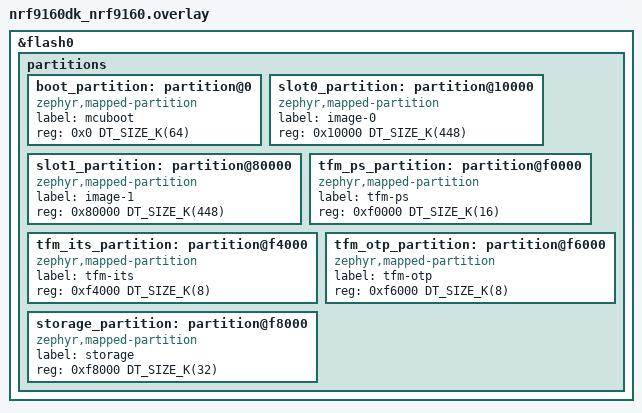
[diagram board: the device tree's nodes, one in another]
/*
 * Copyright (c) 2026 Nordic Semiconductor ASA
 *
 * SPDX-License-Identifier: LicenseRef-Nordic-5-Clause
 */

/delete-node/ &boot_partition;
/delete-node/ &slot0_partition;
/delete-node/ &slot1_partition;
/delete-node/ &storage_partition;
/delete-node/ &tfm_ps_partition;
/delete-node/ &tfm_its_partition;
/delete-node/ &tfm_otp_partition;

&flash0 {
	partitions {
		boot_partition: partition@0 {
			compatible = "zephyr,mapped-partition";
			label = "mcuboot";
			reg = <0x0 DT_SIZE_K(64)>;
		};

		slot0_partition: partition@10000 {
			compatible = "zephyr,mapped-partition";
			label = "image-0";
			reg = <0x10000 DT_SIZE_K(448)>;
		};

		slot1_partition: partition@80000 {
			compatible = "zephyr,mapped-partition";
			label = "image-1";
			reg = <0x80000 DT_SIZE_K(448)>;
		};

		tfm_ps_partition: partition@f0000 {
			compatible = "zephyr,mapped-partition";
			label = "tfm-ps";
			reg = <0xf0000 DT_SIZE_K(16)>;
		};

		tfm_its_partition: partition@f4000 {
			compatible = "zephyr,mapped-partition";
			label = "tfm-its";
			reg = <0xf4000 DT_SIZE_K(8)>;
		};

		tfm_otp_partition: partition@f6000 {
			compatible = "zephyr,mapped-partition";
			label = "tfm-otp";
			reg = <0xf6000 DT_SIZE_K(8)>;
		};

		storage_partition: partition@f8000 {
			compatible = "zephyr,mapped-partition";
			label = "storage";
			reg = <0xf8000 DT_SIZE_K(32)>;
		};
	};
};
